# ESP32-P4-LP register map
Vendor: ESPRESSIF SYSTEMS (SHANGHAI) CO., LTD.; Series: ESP32 P-Series; File version: 3
CPU: RV32IMAC r0p0, little endian, no MPU, no FPU, 0 interrupt priority bits
Address unit: 32 bits
Registers are 32-bit, read-write, reset 0x0 unless marked. A register's access mark holds for its fields unless they carry their own. Offsets are from the block's base; [hi:lo] are bit positions; {n}, {i} and the like mark numbered series.

## LP_TIMER — Low-power Timer
Base 0x50112000
0x00 TAR0_LOW — need_des
  [31:0] MAIN_TIMER_TAR_LOW0
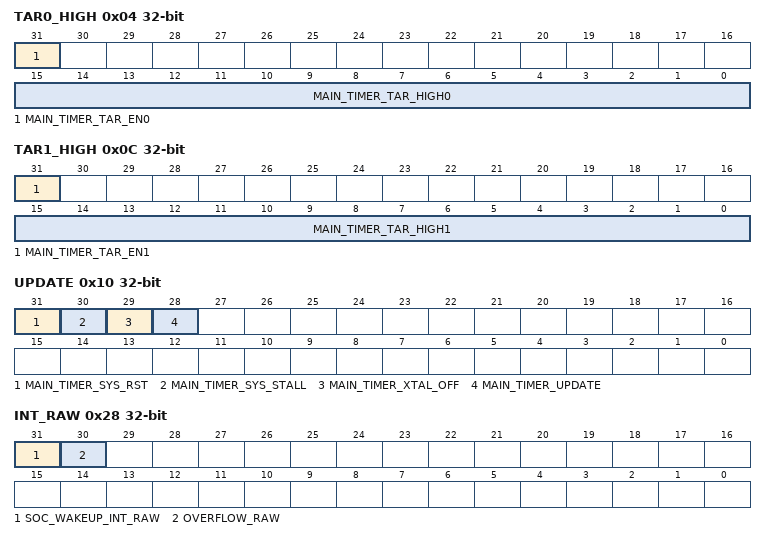
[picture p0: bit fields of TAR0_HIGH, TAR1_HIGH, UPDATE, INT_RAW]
0x04 TAR0_HIGH access per field — need_des
  [31] MAIN_TIMER_TAR_EN0 wo — need_des
  [15:0] MAIN_TIMER_TAR_HIGH0 rw — need_des
0x08 TAR1_LOW — need_des
  [31:0] MAIN_TIMER_TAR_LOW1
0x0C TAR1_HIGH access per field — need_des
  [31] MAIN_TIMER_TAR_EN1 wo — need_des
  [15:0] MAIN_TIMER_TAR_HIGH1 rw — need_des
0x10 UPDATE access per field — need_des
  [31] MAIN_TIMER_SYS_RST rw — need_des
  [30] MAIN_TIMER_SYS_STALL rw — need_des
  [29] MAIN_TIMER_XTAL_OFF rw — need_des
  [28] MAIN_TIMER_UPDATE wo — need_des
0x14 MAIN_BUF0_LOW ro — need_des
  [31:0] MAIN_TIMER_BUF0_LOW
0x18 MAIN_BUF0_HIGH ro — need_des
  [15:0] MAIN_TIMER_BUF0_HIGH
0x1C MAIN_BUF1_LOW ro — need_des
  [31:0] MAIN_TIMER_BUF1_LOW
0x20 MAIN_BUF1_HIGH ro — need_des
  [15:0] MAIN_TIMER_BUF1_HIGH
0x24 MAIN_OVERFLOW wo — need_des
  [31] MAIN_TIMER_ALARM_LOAD
0x28 INT_RAW — need_des
  [31] SOC_WAKEUP_INT_RAW — need_des
  [30] OVERFLOW_RAW — need_des
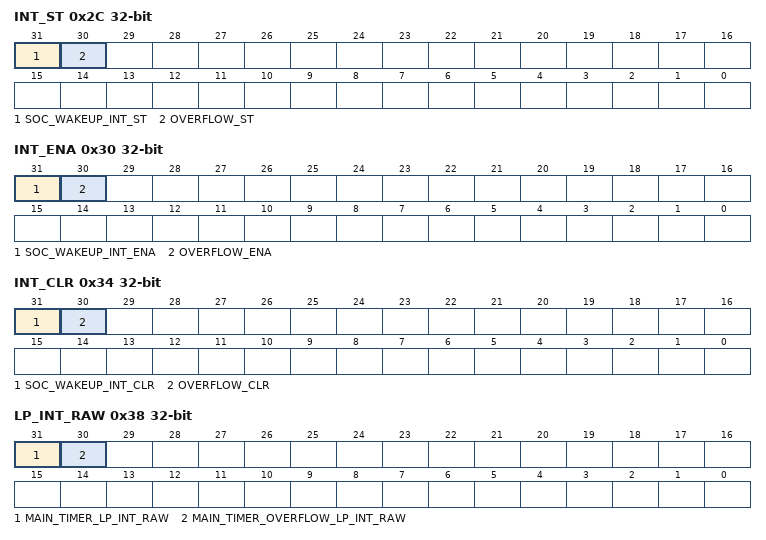
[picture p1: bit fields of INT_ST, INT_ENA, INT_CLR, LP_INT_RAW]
0x2C INT_ST ro — need_des
  [31] SOC_WAKEUP_INT_ST — need_des
  [30] OVERFLOW_ST — need_des
0x30 INT_ENA — need_des
  [31] SOC_WAKEUP_INT_ENA — need_des
  [30] OVERFLOW_ENA — need_des
0x34 INT_CLR wo — need_des
  [31] SOC_WAKEUP_INT_CLR — need_des
  [30] OVERFLOW_CLR — need_des
0x38 LP_INT_RAW — need_des
  [31] MAIN_TIMER_LP_INT_RAW — need_des
  [30] MAIN_TIMER_OVERFLOW_LP_INT_RAW — need_des
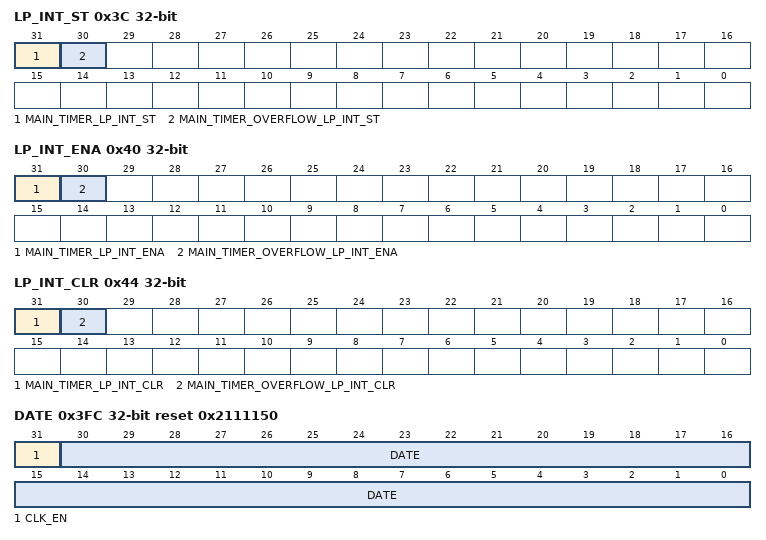
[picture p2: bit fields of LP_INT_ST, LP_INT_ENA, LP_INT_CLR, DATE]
0x3C LP_INT_ST ro — need_des
  [31] MAIN_TIMER_LP_INT_ST — need_des
  [30] MAIN_TIMER_OVERFLOW_LP_INT_ST — need_des
0x40 LP_INT_ENA — need_des
  [31] MAIN_TIMER_LP_INT_ENA — need_des
  [30] MAIN_TIMER_OVERFLOW_LP_INT_ENA — need_des
0x44 LP_INT_CLR wo — need_des
  [31] MAIN_TIMER_LP_INT_CLR — need_des
  [30] MAIN_TIMER_OVERFLOW_LP_INT_CLR — need_des
0x3FC DATE reset 0x2111150 — need_des
  [31] CLK_EN — need_des
  [30:0] DATE — need_des

## LP_TOUCH — LP_TOUCH Peripheral
Base 0x50128000
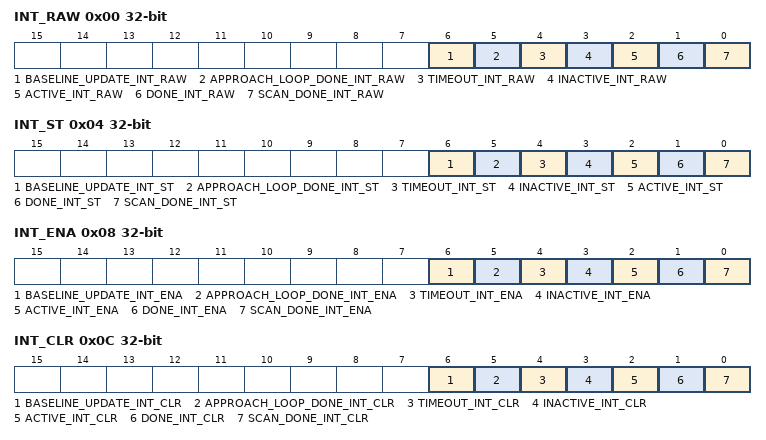
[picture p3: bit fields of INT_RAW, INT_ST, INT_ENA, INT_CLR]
0x00 INT_RAW — need_des
  [6] BASELINE_UPDATE_INT_RAW — need_des
  [5] APPROACH_LOOP_DONE_INT_RAW — need_des
  [4] TIMEOUT_INT_RAW — need_des
  [3] INACTIVE_INT_RAW — need_des
  [2] ACTIVE_INT_RAW — need_des
  [1] DONE_INT_RAW — need_des
  [0] SCAN_DONE_INT_RAW — need_des
0x04 INT_ST ro — need_des
  [6] BASELINE_UPDATE_INT_ST — need_des
  [5] APPROACH_LOOP_DONE_INT_ST — need_des
  [4] TIMEOUT_INT_ST — need_des
  [3] INACTIVE_INT_ST — need_des
  [2] ACTIVE_INT_ST — need_des
  [1] DONE_INT_ST — need_des
  [0] SCAN_DONE_INT_ST — need_des
0x08 INT_ENA — need_des
  [6] BASELINE_UPDATE_INT_ENA — need_des
  [5] APPROACH_LOOP_DONE_INT_ENA — need_des
  [4] TIMEOUT_INT_ENA — need_des
  [3] INACTIVE_INT_ENA — need_des
  [2] ACTIVE_INT_ENA — need_des
  [1] DONE_INT_ENA — need_des
  [0] SCAN_DONE_INT_ENA — need_des
0x0C INT_CLR wo — need_des
  [6] BASELINE_UPDATE_INT_CLR — need_des
  [5] APPROACH_LOOP_DONE_INT_CLR — need_des
  [4] TIMEOUT_INT_CLR — need_des
  [3] INACTIVE_INT_CLR — need_des
  [2] ACTIVE_INT_CLR — need_des
  [1] DONE_INT_CLR — need_des
  [0] SCAN_DONE_INT_CLR — need_des
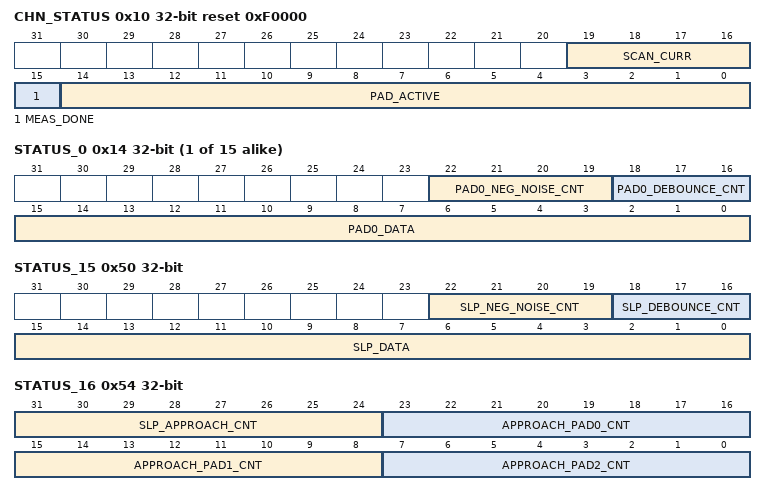
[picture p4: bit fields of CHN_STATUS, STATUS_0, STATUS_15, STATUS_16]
0x10 CHN_STATUS ro reset 0xF0000 — need_des
  [19:16] SCAN_CURR — need_des
  [15] MEAS_DONE — need_des
  [14:0] PAD_ACTIVE — need_des
{0x14+4i} STATUS_{i} ro (i=0..14) — need_des
  [22:19] PAD{i}_NEG_NOISE_CNT — need_des
  [18:16] PAD{i}_DEBOUNCE_CNT — need_des
  [15:0] PAD{i}_DATA — need_des
0x50 STATUS_15 ro — need_des
  [22:19] SLP_NEG_NOISE_CNT — need_des
  [18:16] SLP_DEBOUNCE_CNT — need_des
  [15:0] SLP_DATA — need_des
0x54 STATUS_16 ro — need_des
  [31:24] SLP_APPROACH_CNT — need_des
  [23:16] APPROACH_PAD0_CNT — need_des
  [15:8] APPROACH_PAD1_CNT — need_des
  [7:0] APPROACH_PAD2_CNT — need_des
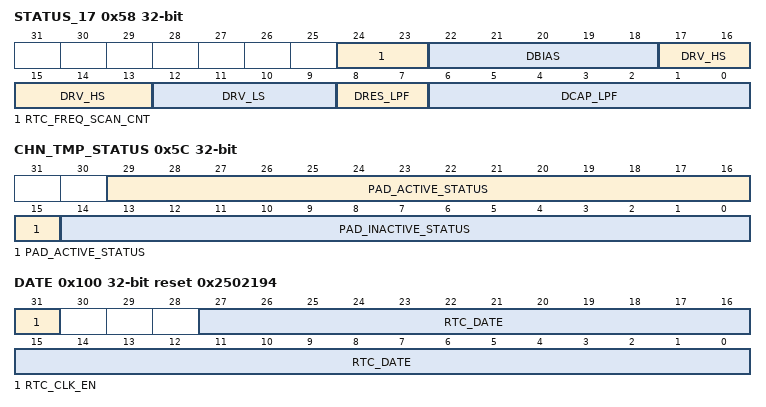
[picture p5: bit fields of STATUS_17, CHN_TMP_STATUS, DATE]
0x58 STATUS_17 ro — need_des
  [24:23] RTC_FREQ_SCAN_CNT — need_des
  [22:18] DBIAS — need_des
  [17:13] DRV_HS — need_des
  [12:9] DRV_LS — need_des
  [8:7] DRES_LPF — need_des
  [6:0] DCAP_LPF — Reserved
0x5C CHN_TMP_STATUS ro — need_des
  [29:15] PAD_ACTIVE_STATUS — need_des
  [14:0] PAD_INACTIVE_STATUS — need_des
0x100 DATE reset 0x2502194 — need_des
  [31] RTC_CLK_EN — need_des
  [27:0] RTC_DATE — need_des
